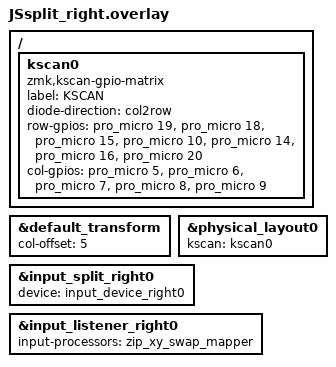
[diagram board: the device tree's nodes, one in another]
#include "JSsplit.dtsi"
#include <input/processors.dtsi>

&default_transform {
    col-offset = <5>;
};

&physical_layout0 {
    kscan = <&kscan0>;
};

/ {
    kscan0: kscan0 {
    compatible = "zmk,kscan-gpio-matrix";
	label = "KSCAN";

	diode-direction = "col2row";
		
	row-gpios = <&pro_micro 19 (GPIO_ACTIVE_HIGH | GPIO_PULL_DOWN)>,
				<&pro_micro 18 (GPIO_ACTIVE_HIGH | GPIO_PULL_DOWN)>,
				<&pro_micro 15 (GPIO_ACTIVE_HIGH | GPIO_PULL_DOWN)>,
				<&pro_micro 10 (GPIO_ACTIVE_HIGH | GPIO_PULL_DOWN)>,
                <&pro_micro 14 (GPIO_ACTIVE_HIGH | GPIO_PULL_DOWN)>,
                <&pro_micro 16 (GPIO_ACTIVE_HIGH | GPIO_PULL_DOWN)>,
				<&pro_micro 20 (GPIO_ACTIVE_HIGH | GPIO_PULL_DOWN)>;
                
    col-gpios = <&pro_micro 5 GPIO_ACTIVE_HIGH>,
                <&pro_micro 6 GPIO_ACTIVE_HIGH>,
                <&pro_micro 7 GPIO_ACTIVE_HIGH>,
                <&pro_micro 8 GPIO_ACTIVE_HIGH>,
                <&pro_micro 9 GPIO_ACTIVE_HIGH>;
    };
};

// == Input devices ==
// Enabling input-split for its own input devices
// Adding input devices and assigning them to input-split
&input_split_right0 {
    status = "okay";
    device = <&input_device_right0>;
};
&input_listener_right0 {
     status = "okay";
     input-processors = <&zip_xy_swap_mapper>; // Swaps X and Y 
};
